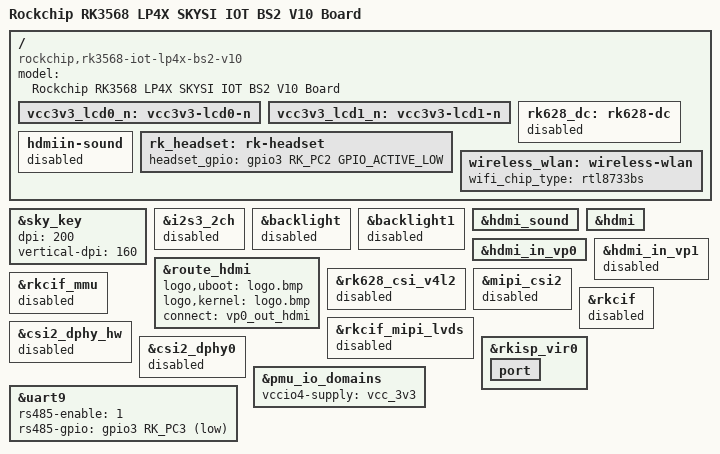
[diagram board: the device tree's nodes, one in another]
// SPDX-License-Identifier: (GPL-2.0+ OR MIT)
/*
 * Copyright (c) 2020 Rockchip Electronics Co., Ltd.
 *
 */

#include "rk3568-evb-lp4x-s1-v12.dtsi"
#include "rk3568-android.dtsi"
/{
	model = "Rockchip RK3568 LP4X SKYSI IOT BS2 V10 Board";
	compatible = "rockchip,rk3568-iot-lp4x-bs2-v10", "rockchip,rk3568";

	vcc3v3_lcd0_n: vcc3v3-lcd0-n {
		/delete-property/ gpio;
	};

	vcc3v3_lcd1_n: vcc3v3-lcd1-n {
		/delete-property/ gpio;
	};

	rk628_dc: rk628-dc {
		status = "disabled";
	};

	hdmiin-sound {
		status = "disabled";
	};

	/delete-node/ simple-audio-card,codec;

	rk_headset: rk-headset {
		headset_gpio = <&gpio3 RK_PC2 GPIO_ACTIVE_LOW>;
	};

	wireless_wlan: wireless-wlan {
		wifi_chip_type = "rtl8733bs";
	};
};

&sky_key{
	dpi = "200";
	vertical-dpi = "160";
	status = "okay";
};

&i2s3_2ch{
	status = "disabled";
};

&backlight {
	status = "disabled";
};

&backlight1 {
	status = "disabled";
};

&hdmi_sound {
	status = "okay";
};

&hdmi {
	status = "okay";
};

&hdmi_in_vp0 {
	status = "okay";
};

&hdmi_in_vp1 {
	status = "disabled";
};

&route_hdmi {
	logo,uboot = "logo.bmp";
	logo,kernel = "logo.bmp";
	connect = <&vp0_out_hdmi>;
	status = "okay";
};

&rk628_csi_v4l2 {
	status = "disabled";
};

&mipi_csi2 {
	status = "disabled";
};

&rkcif_mipi_lvds {
	status = "disabled";
};

&rkcif_mmu {
	status = "disabled";
};

&rkcif {
	status = "disabled";
};

&csi2_dphy_hw {
	status = "disabled";
};

&csi2_dphy0 {
	status = "disabled";
};

&rkisp_vir0 {
	port {
		/delete-node/ endpoint@0;
	};
};

&pmu_io_domains {
	vccio4-supply = <&vcc_3v3>;
};

&uart9 {
	rs485-enable = <1>;
	rs485-gpio = <&gpio3 RK_PC3 GPIO_ACTIVE_LOW>;
};
